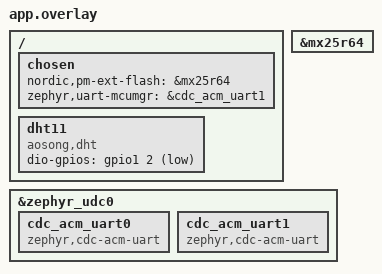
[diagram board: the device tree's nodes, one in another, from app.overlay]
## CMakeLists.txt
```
#
# Copyright (c) 2020 Nordic Semiconductor ASA
#
# SPDX-License-Identifier: LicenseRef-Nordic-5-Clause
#
cmake_minimum_required(VERSION 3.20.0)

find_package(Zephyr REQUIRED HINTS $ENV{ZEPHYR_BASE})
project(chat)

# NORDIC SDK APP START
target_sources(app PRIVATE
	src/main.c
	src/model_handler.c
	src/flash_storage.c)
target_include_directories(app PRIVATE include)
# NORDIC SDK APP END
```

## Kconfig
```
mainmenu "Mesh Node Application"

source "Kconfig.zephyr"

config APP_ENABLE_DFU
    bool "Enable DFU (MCUmgr + External Flash)"
    default y
    help
      Enables MCUmgr, and memory layout for DFU. Disable this for faster dev builds.
      NOTE: You must also enable/disable SB_CONFIG_BOOTLOADER_MCUBOOT in sysbuild.conf!

    # MCUmgr
    select MCUMGR
    select MCUMGR_GRP_OS
    select MCUMGR_GRP_IMG
    select MCUMGR_TRANSPORT_UART
    select IMG_MANAGER
    
    # Memory Layout (External Flash)
    # This tells the partition manager to use the external flash for the secondary slot
    select PM_EXTERNAL_FLASH_MCUBOOT_SECONDARY

    # USB stack - an extra USB CDC Port has to be exposed to the host
    select USB_COMPOSITE_DEVICE
```

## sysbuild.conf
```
# MCUboot
# SB_CONFIG_BOOTLOADER_MCUBOOT=y
# MCUboot should use external flash
# SB_CONFIG_PM_EXTERNAL_FLASH_MCUBOOT_SECONDARY=y

# Config for signing with custom private key
# SB_CONFIG_BOOT_SIGNATURE_KEY_FILE="\${APP_DIR}/private_key.pem"
# SB_CONFIG_BOOT_SIGNATURE_TYPE_ECDSA_P256=y
```

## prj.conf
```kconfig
#
# Copyright (c) 2020 Nordic Semiconductor ASA
#
# SPDX-License-Identifier: LicenseRef-Nordic-5-Clause
#
CONFIG_NCS_SAMPLES_DEFAULTS=y
CONFIG_LOG_MODE_DEFERRED=y

# Config DFU
CONFIG_APP_ENABLE_DFU=n

CONFIG_SENSOR=y
CONFIG_DHT=y

# Dependencies
# Configure dependencies for CONFIG_MCUMGR  
CONFIG_NET_BUF=y
CONFIG_ZCBOR=y
CONFIG_CRC=y

# Flash configs
CONFIG_PARTITION_MANAGER_ENABLED=y
CONFIG_FLASH=y
CONFIG_STREAM_FLASH=y
CONFIG_FLASH_MAP=y
CONFIG_NORDIC_QSPI_NOR_FLASH_LAYOUT_PAGE_SIZE=4096

# Configure dependencies for CONFIG_MCUMGR_TRANSPORT_UART 
CONFIG_BASE64=y

# Enable QSPI driver for Application
CONFIG_NORDIC_QSPI_NOR=y

# Enable USB subsystem
CONFIG_USB_DEVICE_STACK=y
CONFIG_UART_LINE_CTRL=y
CONFIG_USB_CDC_ACM_RINGBUF_SIZE=1024
CONFIG_USB_DEVICE_INITIALIZE_AT_BOOT=n
CONFIG_USB_DEVICE_PID=0x5301
CONFIG_USB_DEVICE_VID=0x1915
CONFIG_USB_DEVICE_PRODUCT="Sensor Node Gateway"

# General configuration
CONFIG_NCS_APPLICATION_BOOT_BANNER_STRING="Sensor Base"
CONFIG_SYSTEM_WORKQUEUE_STACK_SIZE=2048
# Flash shell module uses 8k of RAM for testing buffers, disable to save RAM
CONFIG_FLASH_SHELL=n
CONFIG_NVS=y
CONFIG_NVS_LOOKUP_CACHE=y
CONFIG_SETTINGS=y
CONFIG_SETTINGS_NVS_NAME_CACHE=y
CONFIG_HWINFO=y
CONFIG_DK_LIBRARY=y
CONFIG_PM_PARTITION_SIZE_SETTINGS_STORAGE=0x8000
CONFIG_SOC_FLASH_NRF_PARTIAL_ERASE=y

# Bluetooth configuration
CONFIG_BT=y
CONFIG_BT_DEVICE_NAME="Sensor Base"
CONFIG_BT_L2CAP_TX_BUF_COUNT=8
CONFIG_BT_OBSERVER=y
CONFIG_BT_PERIPHERAL=y
CONFIG_BT_SETTINGS=y

# Disable unused Bluetooth features
CONFIG_BT_CTLR_LE_ENC=n
CONFIG_BT_PHY_UPDATE=n
CONFIG_BT_CTLR_CHAN_SEL_2=n
CONFIG_BT_CTLR_MIN_USED_CHAN=n
CONFIG_BT_CTLR_PRIVACY=n

# Bluetooth Mesh configuration
CONFIG_BT_MESH=y
CONFIG_BT_MESH_RELAY=y
CONFIG_BT_MESH_FRIEND=y
CONFIG_BT_MESH_RX_SEG_MAX=10
CONFIG_BT_MESH_TX_SEG_MAX=10
CONFIG_BT_MESH_PB_GATT=y
CONFIG_BT_MESH_GATT_PROXY=y
CONFIG_BT_MESH_PROXY_USE_DEVICE_NAME=y
CONFIG_BT_MESH_SUBNET_COUNT=2
CONFIG_BT_MESH_APP_KEY_COUNT=3
CONFIG_BT_MESH_MODEL_KEY_COUNT=3
CONFIG_BT_MESH_CRPL=32
CONFIG_BT_MESH_MSG_CACHE_SIZE=64
CONFIG_BT_MESH_DK_PROV=n

# Enable Bluetooth Mesh models debug logs
CONFIG_BT_MESH_LOG_LEVEL_DBG=y

CONFIG_LOG_BACKEND_RTT=n
```

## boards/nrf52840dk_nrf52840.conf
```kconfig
#
# Copyright (c) 2024 Nordic Semiconductor ASA
#
# SPDX-License-Identifier: LicenseRef-Nordic-5-Clause
#
################################################################################
# Application overlay - nrf52dk_nrf52840

CONFIG_SOC_FLASH_NRF_PARTIAL_ERASE=n
CONFIG_SENSOR=y
CONFIG_DHT=y
```

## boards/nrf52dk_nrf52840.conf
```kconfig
#
# Copyright (c) 2024 Nordic Semiconductor ASA
#
# SPDX-License-Identifier: LicenseRef-Nordic-5-Clause
#
################################################################################
# Application overlay - nrf52dk_nrf52840

CONFIG_SOC_FLASH_NRF_PARTIAL_ERASE=n
```

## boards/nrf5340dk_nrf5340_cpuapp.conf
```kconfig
CONFIG_SYSTEM_WORKQUEUE_STACK_SIZE=4096
# Use deferred logging
CONFIG_NCS_SAMPLES_DEFAULTS=n
CONFIG_LOG=y
CONFIG_ASSERT=y
CONFIG_ASSERT_NO_COND_INFO=y
CONFIG_ASSERT_NO_MSG_INFO=y
CONFIG_HW_STACK_PROTECTION=y
```

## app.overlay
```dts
&mx25r64 {
	status = "okay";
};

&zephyr_udc0 {
	cdc_acm_uart0: cdc_acm_uart0 {
		compatible = "zephyr,cdc-acm-uart";
	};

	cdc_acm_uart1: cdc_acm_uart1 {
        compatible = "zephyr,cdc-acm-uart";
    };
};

/ {
	chosen {
		nordic,pm-ext-flash = &mx25r64;
		zephyr,uart-mcumgr = &cdc_acm_uart1;
	};

	dht11: dht11 {
		compatible = "aosong,dht";
		status = "okay";
		dio-gpios = <&gpio1 2 (GPIO_PULL_UP | GPIO_ACTIVE_LOW)>;
	};
};
```

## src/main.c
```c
/*
 * Copyright (c) 2024 Nordic Semiconductor ASA
 *
 * SPDX-License-Identifier: LicenseRef-Nordic-5-Clause
 */

#include <zephyr/kernel.h>
#include <zephyr/bluetooth/bluetooth.h>
#include <zephyr/bluetooth/mesh.h>
#include <zephyr/logging/log.h>
#include <zephyr/settings/settings.h>
#include <dk_buttons_and_leds.h>
#include <zephyr/drivers/hwinfo.h>
#include <zephyr/sys/reboot.h>
#include <zephyr/drivers/uart.h>
#include <zephyr/usb/usb_device.h>
#include <zephyr/drivers/gpio.h>
#include <zephyr/devicetree.h>
#include <pm_config.h>
#include <zephyr/drivers/flash.h>
#include <zephyr/storage/flash_map.h>
#include <zephyr/sys/byteorder.h>
#include "model_handler.h"
#include "flash_storage.h"

#if defined(CONFIG_SOC_SERIES_NRF52X)
#include <zephyr/drivers/sensor.h>
#endif

LOG_MODULE_REGISTER(main, LOG_LEVEL_INF);

// TODO: Remove this counter once data is available from sensors
static uint32_t app_counter = 0;
static struct gpio_callback btn_cb;
static enum usb_dc_status_code current_usb_status = USB_DC_DISCONNECTED;
static bool is_central = false;

#if defined(CONFIG_SOC_SERIES_NRF52X)
const struct device *dht11 = DEVICE_DT_GET(DT_NODELABEL(dht11));
#endif

#define SNS_READ_INTERVAL_MS 60000
#define SNS_THREAD_STACK_SIZE 1024
#define SNS_THREAD_PRIORITY 7
#define SENDER_THREAD_STACK_SIZE 2048
#define SENDER_THREAD_PRIORITY 7
#define ERASE_FLASH_THREAD_STACK_SIZE 1024
#define ERASE_FLASH_THREAD_PRIORITY 7
#define SNS_Q_SIZE MAX_BATCH_SIZE
K_MSGQ_DEFINE(sns_msg_q, sizeof(struct sensor_message), SNS_Q_SIZE, 4);

// Semaphore for the thread reading the sensors
K_SEM_DEFINE(sample_sem, 0, 1);
// Semaphore for the thread that handles the queued readings
K_SEM_DEFINE(send_samples_sem, 0, 1);
// Semaphore for the thread that calls the erase flash function
K_SEM_DEFINE(erase_flash_sem, 0, 1);

// Get devicetree node identifiers for LEDs and buttons
#define LED0_NODE DT_ALIAS(led0)
#define LED1_NODE DT_ALIAS(led1)
#define LED2_NODE DT_ALIAS(led2)
#define LED3_NODE DT_ALIAS(led3)

#define BTN0_NODE DT_ALIAS(sw0)
#define BTN1_NODE DT_ALIAS(sw1)
#define BTN2_NODE DT_ALIAS(sw2)
#define BTN3_NODE DT_ALIAS(sw3)

static const struct gpio_dt_spec leds[] = {
    GPIO_DT_SPEC_GET(LED0_NODE, gpios),
    GPIO_DT_SPEC_GET(LED1_NODE, gpios),
    GPIO_DT_SPEC_GET(LED2_NODE, gpios),
    GPIO_DT_SPEC_GET(LED3_NODE, gpios)
};

#define USB_CONN_LED (leds[0])
#define CENTRAL_LED  (leds[1])
#define LED_ON       1
#define LED_OFF      0


// Function that will be passed as cb to model_handler
static void led_control(uint32_t led_mask) {
    for (uint8_t i = 0; i < ARRAY_SIZE(leds); i++) {
        if (led_mask & BIT(i))
            gpio_pin_set_dt(&(leds[i]), LED_ON);
        else
            gpio_pin_set_dt(&(leds[i]), LED_OFF);
    }
}

static const struct gpio_dt_spec btns[] = {
    GPIO_DT_SPEC_GET(BTN0_NODE, gpios),
    GPIO_DT_SPEC_GET(BTN1_NODE, gpios),
    GPIO_DT_SPEC_GET(BTN2_NODE, gpios),
    GPIO_DT_SPEC_GET(BTN3_NODE, gpios)
};

static void button_handler(const struct device *dev, struct gpio_callback *cb, uint32_t pins) {
    // Check if any of the buttons has triggered this interrupt
    // All buttons are on GPIO Port 0, so it's safe to check *dev against a single button
    if (dev == btns[0].port) {
        if (pins & BIT(btns[0].pin)) {
            // Pressing btn0 (Button 1 on the board) generates a new sample
            k_sem_give(&sample_sem);
        }

        if (pins & BIT(btns[1].pin)) {
            // Pressing btn1 (Button 2 on the board) handles existing readings stored in queue
            k_sem_give(&send_samples_sem);
        }

        if (pins & BIT(btns[2].pin)) {
            // Pressing btn2 (Button 3 on the board) clears the external flash
            k_sem_give(&erase_flash_sem);
        }
    }
}

// UUID so device is recognised, value will be the same correspond as the MCU HW UUID
static uint8_t dev_uuid[16];

// Boolean for available USB connection status - true if board is connected to a host via the MCU USB header
static volatile bool is_usb_conn = false;

// Get the CDC ACM UART device from the Overlay
const struct device *usb_uart_dev = DEVICE_DT_GET(DT_NODELABEL(cdc_acm_uart0));

static void uart_rx_cb(const struct device *dev, void *user_data) {
    if (!uart_irq_update(dev)) {
        return;
    }

    if (uart_irq_rx_ready(dev)) {
        uint8_t c;
        while (uart_fifo_read(dev, &c, 1) == 1) {
            // Simple command parse - receiving 'C' lets the node know it's now the central
            if (c == 'C') {
                LOG_INF("Received 'Set Central'");
                model_handler_est_central();
                gpio_pin_set_dt(&CENTRAL_LED, LED_ON);
                is_central = true;
            } else if (c == 'D') {
                LOG_INF("Received 'Cancel Central'");
                model_handler_cancel_central();
                gpio_pin_set_dt(&CENTRAL_LED, LED_OFF);
            }
        }
    }
}

static void gateway_data_handler(const uint8_t *data, const uint8_t len, const uint16_t addr) {
    if (!is_central || !device_is_ready(usb_uart_dev)) {
        return;
    }

    uint8_t usb_buf[MAX_SNS_MSG_LEN + 10]; // Buffer for central, should be large enough to fit incoming message + serial protocol overhead
    
    // Copy the data into local buffer
    // The 4 byte offset is to leave space for the protocol header 
    memcpy(usb_buf+4, data, len);
    
    // Add sync bytes
    usb_buf[0] = 'R';
    usb_buf[1] = 'X';
    
    // Add sender address
    usb_buf[2] = (uint8_t)(addr & 0xFF); // Extract low byte
    usb_buf[3] = (uint8_t)(addr >> 8); // Extract high byte
    
    // Add end byte
    usb_buf[4+len] = '\0';

    // Send data over USB
    for (uint8_t i = 0; i < 4+len+1; i++) {
        uart_poll_out(usb_uart_dev, usb_buf[i]);
    }
}

static void provisioning_complete(uint16_t net_idx, uint16_t addr) {
    LOG_INF("Provisioning complete! NetIdx: 0x%04x, Address: 0x%04x", net_idx, addr);
    configure_model();
}

static void provisioning_reset(void) {
    // Connection settings should be wiped by the stack when a node is reset by the provisioner
    // Rebooting should ensure that advertising starts from a clean state
    // TODO: Add network core force off before reboot if there are issues with peripherals after a restart.
    LOG_WRN("Node reset. Rebooting.");
    sys_reboot(SYS_REBOOT_WARM);
}

static const struct bt_mesh_prov prov = {
    .uuid = dev_uuid,
    .complete = provisioning_complete,
    .reset = provisioning_reset,
};

static void usb_status_cb(enum usb_dc_status_code cb_status, const uint8_t *param) {
    current_usb_status = cb_status;
    switch (cb_status) {
        case USB_DC_CONNECTED: 
            LOG_INF("USB Power");
            break;
        case USB_DC_CONFIGURED:
            LOG_INF("USB Configured");
            is_usb_conn = true;
            gpio_pin_set_dt(&USB_CONN_LED, LED_ON);
            
            // Start listening for 'Set Central' command
            uart_irq_rx_enable(usb_uart_dev);
            break;
        case USB_DC_RESUME:
            LOG_INF("USB Resumed");
            is_usb_conn = true;
            gpio_pin_set_dt(&USB_CONN_LED, LED_ON);
            uart_irq_rx_enable(usb_uart_dev);
            break;
        case USB_DC_DISCONNECTED:
        case USB_DC_SUSPEND:
            LOG_INF("USB Disconnected");
            is_usb_conn = false;
            gpio_pin_set_dt(&USB_CONN_LED, LED_OFF);
            gpio_pin_set_dt(&CENTRAL_LED, LED_OFF);

            // Stop listening to USB port
            uart_irq_rx_disable(usb_uart_dev);
            // Let the other devices know this node is no longer a central
            if (is_central) {
                gpio_pin_set_dt(&CENTRAL_LED, LED_OFF);
                is_central = false;
                model_handler_cancel_central();
            }
            break;
        default:
            ;
            break;
    }
}

static void enq_reading(struct k_msgq *q, const struct sensor_message *sm) {
    // TODO: Revisit and evaluate if 20ms of wait time is an acceptable value 
    int err = k_msgq_put(q, sm, K_MSEC(20));
    if (err == -ENOMSG || err == -EAGAIN) {
        // Queue is probably full. Remove an element and try again
        struct sensor_message temp;
        k_msgq_get(q, &temp, K_MSEC(50));
        if (k_msgq_put(q, sm, K_MSEC(200))) {
            LOG_WRN("Unable to add reading to queue");
        }
        else {
            LOG_DBG("Queue full, overwrote old sample");
        }
    } else {
        LOG_DBG("Sample enqueued. Count: %u", k_msgq_num_used_get(q));
    }
}

// Function that reads sensors (simulated for now) and adds received values to a queue of readings
static void gen_samples_and_enq(void) {
    static struct sensor_message msg;

    app_counter++;
    msg.timestamp = k_uptime_get_32();

#if defined(CONFIG_SOC_SERIES_NRF52X)
    int err = sensor_sample_fetch(dht11);
    if (err) {
        LOG_ERR("Failed to get sample from DHT11 (err %d)", err);
        return;
    }

    struct sensor_value temp;
    struct sensor_value humid;

    err = sensor_channel_get(dht11, SENSOR_CHAN_AMBIENT_TEMP, &temp);
    if (!err) {
        LOG_WRN("GOT TEMP: %d.%d", temp.val1, temp.val2/10000);
        msg.type = SENSOR_TYPE_TEMP_C;
        msg.value = temp.val1*100 + temp.val2/10000;
        enq_reading(&sns_msg_q, &msg);

        err = sensor_channel_get(dht11, SENSOR_CHAN_HUMIDITY, &humid);
        if (err) {
            LOG_ERR("Failed to read humidity from DHT11 (err %d)", err);
        } else {
            LOG_WRN("GOT HUMID: %d.%d", humid.val1, humid.val2/10000);
            msg.type = SENSOR_TYPE_HUMID_PC;
            msg.value = humid.val1*100 + humid.val2/10000;
            enq_reading(&sns_msg_q, &msg);
        }
    } else {
        LOG_ERR("Failed to read temperature from DHT11 (err %d)", err);
    }
#elif defined(CONFIG_SOC_SERIES_NRF53X)
    // Generate a counter reading
    msg.type = SENSOR_TYPE_COUNTER;
    msg.value = app_counter;
    // Try to queue message
    enq_reading(&sns_msg_q, &msg);

    // Generate a temperature or humidity reading
    if (app_counter % 2) {
        msg.type = SENSOR_TYPE_TEMP_C;
        msg.value = 2450 + (app_counter % 50); // For some variation in the values
        if (app_counter % 8) {
            msg.value = -msg.value;
        }
    } else {
        msg.type = SENSOR_TYPE_HUMID_PC;
        msg.value = 50 + (10 - (app_counter % 21));
    }
    enq_reading(&sns_msg_q, &msg);
#endif
    // If the queue is almost full, try to empty it
    if (k_msgq_num_free_get(&sns_msg_q) < 2) {
        k_sem_give(&send_samples_sem);
    }
}

// Thread that reads sensors periodically
static void sns_thread_f(void *p1, void *p2, void *p3) {
    int ret = 0;
    while (1) {
        ret = k_sem_take(&sample_sem, K_MSEC(SNS_READ_INTERVAL_MS));
        LOG_INF("Generating samples");
        gen_samples_and_enq();
    }
}

K_THREAD_DEFINE(sns_thread, SNS_THREAD_STACK_SIZE, sns_thread_f, 
                NULL, NULL, NULL, SNS_THREAD_PRIORITY, 0, 0);

// Thread to offload sending from the button interrupt handler
static void sender_thread_f(void *p1, void *p2, void *p3) {
    int ret = 0, err = 0;
    struct sensor_message batch[MAX_BATCH_SIZE];
    uint8_t buf[MAX_SNS_MSG_LEN];
    
    while (1) {
        ret = k_sem_take(&send_samples_sem, K_FOREVER);

        if (ret) {
            LOG_ERR("Failed to take send_sample_sem");
            continue;
        }

        // Peek to check if there is data to process
        while (k_msgq_num_used_get(&sns_msg_q) > 0) { 
            uint8_t count = 0;
    
            // Prepare Batch
            while (count < MAX_BATCH_SIZE && k_msgq_get(&sns_msg_q, &batch[count], K_MSEC(10)) == 0) {
                count++;
            }
    
            if (count) {
                if (is_central) {
                    // If the node is the central, send data over USB directly
                    // Also announce that node is central in case any other nodes joined the network
                    // and are unaware
                    model_handler_est_central();
                    memset(buf, 0, sizeof(buf));
                    buf[0] = count;
                    int offset = 1;

                    // Serialize the batch
                    for (int i = 0; i < count; i++) {
                        buf[offset++] = batch[i].type;

                        sys_put_le32(batch[i].timestamp, &buf[offset]);
                        offset += sizeof(batch[i].timestamp);

                        sys_put_le32(batch[i].value, &buf[offset]);
                        offset += sizeof(batch[i].value);
                    }

                    gateway_data_handler(buf, offset, get_central_address());
                } else if (central_exists()) {
                    // try to send data to central
                    err = model_handler_send(batch, count);
                    
                    if (err == -EBUSY) {
                        LOG_WRN("Mesh stack busy (err %d), reattempting transmission shortly", err);

                        k_msleep(1000);
                        err = model_handler_send(batch, count);
                        if (err) {
                            LOG_ERR("Retransmission failed (err %d). Storing data in flash", err);

                            for (int i = 0; i < count; i++) {
                                flash_storage_write(&batch[i]);
                            }
                        }
                    }
                } else {
                    // Node isn't connected to USB and no central is available, store readings in flash
                    LOG_INF("No connection available (USB or Mesh), storing data in flash");
                    for (int i = 0; i < count; i++) {
                        flash_storage_write(&batch[i]);
                    }
                }
            }
        }
    }
}

K_THREAD_DEFINE(sender_thread, SENDER_THREAD_STACK_SIZE, sender_thread_f, 
                NULL, NULL, NULL, SENDER_THREAD_PRIORITY, 0, 0);

static void erase_flash_thread_f(void *p1, void *p2, void *p3) {
    int err = 0;
    while (1) {
        k_sem_take(&erase_flash_sem, K_FOREVER);
        LOG_INF("Erasing flash");
        err = flash_storage_clear();
        if (err) {
            LOG_ERR("Flash erase failed (err %d)", err);
        }
    }
}

K_THREAD_DEFINE(erase_flash_thread, ERASE_FLASH_THREAD_STACK_SIZE, erase_flash_thread_f, 
                NULL, NULL, NULL, ERASE_FLASH_THREAD_PRIORITY, 0, 0);

int main(void)
{
    int err;

    LOG_INF("Initializing Bare-Bones BLE Mesh Vendor Sample");

    // Check if LED and Buttons port is ready - they are all on port 0
    if (!device_is_ready(leds[0].port)) {
        LOG_ERR("LEDs and Buttons GPIO port is not ready");
        return 0;
    }

    // Configure LED pins
    for (uint8_t i = 0; i < ARRAY_SIZE(leds); i++) {
        err = gpio_pin_configure_dt(&(leds[i]), GPIO_OUTPUT_ACTIVE);
        if (err) {
            LOG_ERR("LEDs configuration failed (err %d)", err);
            return err;
        }
    }

    // Configure Button pins
    for (uint8_t i = 0; i < ARRAY_SIZE(btns); i++) {
        err = gpio_pin_configure_dt(&(btns[i]), GPIO_INPUT);
        if (err) {
            LOG_ERR("Buttons configuration failed (err %d)", err);
            return err;
        }
    }

    // Configure Button interrupts
    for (uint8_t i = 0; i < ARRAY_SIZE(btns); i++) {
        err = gpio_pin_interrupt_configure_dt(&(btns[i]), GPIO_INT_EDGE_TO_ACTIVE);
        if (err) {
            LOG_ERR("Button interrupts config failed (err %d)", err);
            return err;
        }
    } 

    // Configure Button interrupt callback
    // Create mask that includes all buttons
    uint32_t btn_mask = 0;
    for (uint8_t i = 0; i < ARRAY_SIZE(btns); i++) {
        btn_mask |= BIT(btns[i].pin);
    }
    // Init cb structure
    gpio_init_callback(&btn_cb, button_handler, btn_mask);
    // Add cb to buttons
    for (uint8_t i = 0; i < ARRAY_SIZE(btns); i++) {
        err = gpio_add_callback(btns[i].port, &btn_cb);
		if (err) {
			LOG_ERR("Cannot add callback (err %d)", err);
			return err;
		}
    }

    err = flash_storage_init();
    if (err) {
        LOG_ERR("Flash Storage Init Failed (%d)", err);
    }

    err = model_handler_init((struct model_cbs) {.gw_cb = gateway_data_handler, .led_cb = led_control});
    if (err) {
        LOG_ERR("Model handler init failed (err %d)", err);
        return err;
    }

#if defined(CONFIG_SOC_SERIES_NRF52X)
    if (!dht11) {
        LOG_ERR("DHT sensor not found");
    } else if (!device_is_ready(dht11)) {
        LOG_ERR("DHT sensor not ready");
    } else {
        LOG_INF("DHT sensor found and ready");
    }
#endif

    if (!device_is_ready(usb_uart_dev)) {
        LOG_ERR("CDC ACM device not ready");
        return -ENODEV;
    }

    // Configure UART Interrupt Callback
    uart_irq_callback_user_data_set(usb_uart_dev, uart_rx_cb, NULL);

    // Enable USB stack for DFU and recovery
    if (IS_ENABLED(CONFIG_USB_DEVICE_STACK)) {
		int err = usb_enable(usb_status_cb);
		if (err) {
            LOG_ERR("USB stack init failed (err %d)", err);
			return 0;
		}
	}

    err = bt_enable(NULL);
    if (err) {
        LOG_ERR("Bluetooth init failed (err %d)", err);
        return err;
    }
    LOG_INF("Bluetooth initialized");

    err = hwinfo_get_device_id(dev_uuid, sizeof(dev_uuid));
    if (err < 0) {
        LOG_WRN("Failed to get device ID (err %d), using random UUID", err);
        bt_rand(dev_uuid, sizeof(dev_uuid));
    }

    // Provisioning data is populated above
    // Composition data is populated in model_handler.c
    err = bt_mesh_init(&prov, &comp);
    if (err) {
        LOG_ERR("Mesh init failed (err %d)", err);
        return err;
    }

    // Reload connection data if persistent storage is configured
	if (IS_ENABLED(CONFIG_SETTINGS)) {
		settings_load();
	}

    // Start advertising
	// This will be a no-op if settings_load() loaded provisioning info
	bt_mesh_prov_enable(BT_MESH_PROV_ADV | BT_MESH_PROV_GATT);

    LOG_INF("Mesh initialized. Waiting for provisioning...");
    LOG_INF("Once provisioned, press button 1 to generate data");

    // Enable all LEDs as a sign that the app has started. This can be useful after a DFU, as 
    // the bootloader may take a while to copy the new image and launch it
    for (uint8_t i = 0; i < ARRAY_SIZE(leds); i++) {
        gpio_pin_set_dt(&(leds[i]), LED_ON);
    }
    // The LEDs can be turned off after 700ms. Blocking delay is ok atm since main isn't doing anything else after this point.
    k_msleep(700);
    for (uint8_t i = 0; i < ARRAY_SIZE(leds); i++) {
        gpio_pin_set_dt(&(leds[i]), LED_OFF);
    }
    // Turn the USB Conn LED back on if the board is connected to a host
    if (is_usb_conn)
        gpio_pin_set_dt(&USB_CONN_LED, LED_ON);
    if (is_central)
        gpio_pin_set_dt(&CENTRAL_LED, LED_ON);
        
    return 0;
}
```

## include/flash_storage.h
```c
/*
 * flash_storage.h
 *
 * Slot-Based Circular Buffer on Raw Flash.
 */

#ifndef FLASH_STORAGE_H__
#define FLASH_STORAGE_H__

#include <zephyr/kernel.h>
#include <zephyr/drivers/flash.h>
#include "model_handler.h" 

// Maximum entries to buffer in RAM for batch operations
#define FLASH_BATCH_SIZE 10

/**
 * @brief Initialize the flash storage system.
 * Scans metadata to restore the write cursor.
 * @return 0 on success, negative errno on failure.
 */
int flash_storage_init(void);

/**
 * @brief Store a single reading.
 * Writes to the current sector. If full, moves to next sector and erases it.
 * @param msg The sensor reading to store.
 */
void flash_storage_write(const struct sensor_message *msg);

/**
 * @brief Read readings from storage.
 * Reads 'count' items from the ACTIVE slot (newest data).
 * @param msgs Output buffer.
 * @param count Max number to read.
 * @return Number of items read.
 */
int flash_storage_read(struct sensor_message *msgs, int count);

/**
 * @brief Get total number of stored records across all slots.
 */
uint32_t flash_storage_get_count(void);

/**
 * @brief Wipe the entire storage partition.
 */
int flash_storage_clear(void);

#endif /* FLASH_STORAGE_H__ */
```

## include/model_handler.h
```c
#ifndef MODEL_HANDLER_H__
#define MODEL_HANDLER_H__

#include <zephyr/bluetooth/mesh.h>

// Test company and vendor ID
#define TEST_VND_COMPANY_ID 0xFFFF
#define TEST_VND_MODEL_ID   0x0001

// Custom OpCode: 3-byte header for Vendor Models (C0 | ID) + Company ID
#define BT_MESH_MODEL_OP_MESSAGE BT_MESH_MODEL_OP_3(0x01, TEST_VND_COMPANY_ID)
#define BT_MESH_MODEL_OP_EST_CENTRAL BT_MESH_MODEL_OP_3(0x02, TEST_VND_COMPANY_ID)
#define BT_MESH_MODEL_OP_CANCEL_CENTRAL BT_MESH_MODEL_OP_3(0x03, TEST_VND_COMPANY_ID)

// Maximum amount of readings in a single transmission
#define MAX_BATCH_SIZE 10

// Callback type for sending data to the Gateway
typedef void (*gateway_data_cb_t)(const uint8_t *data_buf, const uint8_t len, const uint16_t addr);

// Callback for LED control
typedef void (*led_control_cb_t)(uint32_t led_mask);

// Structure to hold and pass the callbacks
struct model_cbs {
    /**
     * This callback is used by all nodes whenever a packet is received, but it only has an effect
     * if the node also acts as a gateway (is connected to a host via USB).
     */
    gateway_data_cb_t gw_cb;

    /**
     * Callback used by the health server to blink the LEDs during provisioning.
     */
    led_control_cb_t led_cb;
};

// Sensor types that the node can read and send data for
enum sensor_type {
    SENSOR_TYPE_COUNTER = 0,
    SENSOR_TYPE_TEMP_C,
    SENSOR_TYPE_HUMID_PC,
    SENSOR_TYPE_BATT_MV,
};

// Payload structure - limited to 9 bytes for now so it can use unfragmented transmission
struct sensor_message {
    uint8_t type; // Using enum sensor_type would make this field 4 bits, as it would be considered an int
    uint32_t timestamp;
    int32_t value;
};
#define SENSOR_PAYLOAD_LEN (sizeof(uint8_t) + sizeof(uint32_t) + sizeof(int32_t))
// Minimum length of over the air message - 1 byte for count + 1 sensor reading
#define MIN_SNS_MSG_LEN (1 + SENSOR_PAYLOAD_LEN)
#define MAX_SNS_MSG_LEN (1 + (MAX_BATCH_SIZE * SENSOR_PAYLOAD_LEN))

// Mesh model composition
extern const struct bt_mesh_comp comp;

/**
 * @brief Set default publication and subscription parameters (group address, TTL and retransmission policy)
 */
void configure_model(void);

/**
 * @brief Initialize the mesh model subsystem
 * @param _mdl_cbs Struct containing function pointers to the callback implementations
 * @return 0 on success, negative error code otherwise
 */
int model_handler_init(const struct model_cbs _mdl_cbs);

/**
 * @brief Send a structured sensor message
 * @param msgs Array of sensor messages
 * @param count Number of messages in the array
 * @return 0 on success, or negative error code
 */
int model_handler_send(struct sensor_message *msgs, uint8_t count);

/**
 * @brief Establish if a node becomes a central when it's connected to a USB port
 * @return 0 on success or negative error code
 */
int model_handler_est_central(void);

/**
 * @brief Called when a node is disconnected from its USB host to cancel its status as a central;
 * @return on success or negative error code
 */
int model_handler_cancel_central(void);

/**
 * @brief Get the mesh address of the node
 * @return mesh address
 */
uint16_t get_central_address();

/**
 * @brief Check if a central node is known
 * @return 1 if there is a central node, 0 otherwise
 */
bool central_exists();

#endif /* MODEL_HANDLER_H__ */
```

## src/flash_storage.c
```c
/*
 * flash_storage.c
 */

#include <zephyr/kernel.h>
#include <zephyr/logging/log.h>
#include <zephyr/devicetree.h>
#include <zephyr/drivers/flash.h>
#include <zephyr/sys/byteorder.h>
#include <zephyr/sys/util.h>
#include "flash_storage.h"
#include <pm_config.h> 

LOG_MODULE_REGISTER(flash_storage, LOG_LEVEL_INF);

// Flash layout configs
#define SECTOR_SIZE             CONFIG_NORDIC_QSPI_NOR_FLASH_LAYOUT_PAGE_SIZE
#define STORAGE_PARTITION_ID    PM_DATA_STORAGE_ID
#define STORAGE_START_OFFSET    PM_DATA_STORAGE_OFFSET
#define STORAGE_TOTAL_SIZE      PM_DATA_STORAGE_SIZE
const struct device *flash_dev = DEVICE_DT_GET(DT_CHOSEN(nordic_pm_ext_flash));

/** 
 * Layout:
 * Slots 0..N-1: Data
 * Slot N: Metadata
 */
#define META_SECTOR_SIZE        SECTOR_SIZE
#define MAX_SLOTS               ((STORAGE_TOTAL_SIZE / SECTOR_SIZE) - 1)
#define USED_SLOTS              2
#define META_REGION_ADDR        (STORAGE_START_OFFSET + (USED_SLOTS * SECTOR_SIZE))

// Align entry to 4 bytes
#define ENTRY_SIZE              ROUND_UP(sizeof(struct sensor_message), 4)
#define ENTRIES_PER_SECTOR      (SECTOR_SIZE / ENTRY_SIZE)

// Persistent Context
#define CTX_MAGIC               0xDEADBEEF

struct flash_ctx {
    uint32_t magic;
    uint32_t current_slot;           // Index 0 to USED_SLOTS-1
    uint32_t write_offset;           // Byte offset within the current slot
    uint32_t total_count;            // Total records stored (approx)
    uint8_t  slot_valid[USED_SLOTS]; // 1 if slot is full
};

// In-Memory State
static struct flash_ctx ctx;
static uint32_t meta_write_offset = 0;

static bool is_blank(const uint8_t *buf, size_t len)
{
    for (size_t i = 0; i < len; i++) {
        if (buf[i] != 0xFF) return false;
    }
    return true;
}

static int save_context(void)
{
    ctx.magic = CTX_MAGIC;

    // Check if meta sector is full
    if (meta_write_offset + sizeof(struct flash_ctx) > META_SECTOR_SIZE) {
        LOG_INF("Meta sector full, erasing");
        int err = flash_erase(flash_dev, META_REGION_ADDR, META_SECTOR_SIZE);
        if (err != 0) return err;
        meta_write_offset = 0;
    }

    int err = flash_write(flash_dev, META_REGION_ADDR + meta_write_offset, &ctx, sizeof(struct flash_ctx));
    if (err == 0) {
        meta_write_offset += sizeof(struct flash_ctx);
    }
    return err;
}

int flash_storage_init(void)
{
    if (!device_is_ready(flash_dev)) {
        LOG_ERR("Flash device not ready");
        return -ENODEV;
    }

    // Restore Context
    struct flash_ctx temp;
    uint32_t off = 0;
    bool found = false;

    while (off + sizeof(struct flash_ctx) <= META_SECTOR_SIZE) {
        int err = flash_read(flash_dev, META_REGION_ADDR + off, &temp, sizeof(temp));
        if (err != 0) return err;

        if (temp.magic == CTX_MAGIC) {
            ctx = temp;
            found = true;
        } else if (is_blank((uint8_t *)&temp, sizeof(temp))) {
            meta_write_offset = off;
            break;
        }
        off += sizeof(struct flash_ctx);
    }

    if (!found) {
        LOG_INF("No context found. Formatting");
        ctx.magic = CTX_MAGIC;
        ctx.current_slot = 0;
        ctx.write_offset = 0;
        ctx.total_count = 0;
        memset(ctx.slot_valid, 0, sizeof(ctx.slot_valid));
        meta_write_offset = 0;
        
        // Erase first data slot to be ready
        flash_erase(flash_dev, STORAGE_START_OFFSET, SECTOR_SIZE);
        save_context();
    } else {
        if (off >= META_SECTOR_SIZE) meta_write_offset = META_SECTOR_SIZE;
    }

    LOG_INF("Storage Ready: Slot %d, Offset %d, Count %d", 
            ctx.current_slot, ctx.write_offset, ctx.total_count);
    return 0;
}

void flash_storage_write(const struct sensor_message *msg)
{
    // Check if current slot is full
    if (ctx.write_offset + ENTRY_SIZE > SECTOR_SIZE) {
        // Move to next slot
        ctx.slot_valid[ctx.current_slot] = 1; // Mark old slot as full/valid
        
        ctx.current_slot = (ctx.current_slot + 1) % USED_SLOTS;
        LOG_INF("Switching to slot %d", ctx.current_slot);
        ctx.write_offset = 0;
        
        
        // Check if the new target slot already has data (Wrapping around)
        if (ctx.slot_valid[ctx.current_slot]) {
            // A full sector of old data is getting erased
            if (ctx.total_count >= ENTRIES_PER_SECTOR) {
                ctx.total_count -= ENTRIES_PER_SECTOR;
            } else {
                ctx.total_count = 0; // Should not happen if logic is correct
            }
        }
        
        // Erase the new target slot
        uint32_t sector_addr = STORAGE_START_OFFSET + (ctx.current_slot * SECTOR_SIZE);
        flash_erase(flash_dev, sector_addr, SECTOR_SIZE);

        // Mark new slot as technically valid (in use)
        ctx.slot_valid[ctx.current_slot] = 1; 
    }

    // Write to Flash
    uint32_t addr = STORAGE_START_OFFSET + (ctx.current_slot * SECTOR_SIZE) + ctx.write_offset;
    int err = flash_write(flash_dev, addr, msg, sizeof(struct sensor_message));
    
    if (err == 0) {
        ctx.write_offset += ENTRY_SIZE;
        ctx.total_count++;
        save_context();
    } else {
        LOG_ERR("Write failed: %d", err);
    }
}

int flash_storage_read(struct sensor_message *msgs, int count)
{
    /** 
     * Simple Read: Reads 'count' messages from the CURRENT active slot (newest data).
     * Does not iterate backwards through previous slots yet.
     */
    int read = 0;
    uint32_t off = 0;
    uint32_t base_addr = STORAGE_START_OFFSET + (ctx.current_slot * SECTOR_SIZE);

    while (read < count && off < ctx.write_offset) {
        flash_read(flash_dev, base_addr + off, &msgs[read], sizeof(struct sensor_message));
        read++;
        off += ENTRY_SIZE;
    }
    return read;
}

uint32_t flash_storage_get_count(void)
{
    uint32_t cnt = 0;
    for (int i = 0; i < USED_SLOTS; i++) {
        if (ctx.slot_valid[i]) {
            if (i == ctx.current_slot) {
                cnt += (ctx.write_offset / ENTRY_SIZE);
            } else {
                cnt += ENTRIES_PER_SECTOR;
            }
        }
    }
    return cnt;
}

int flash_storage_clear(void)
{
    LOG_INF("Clearing flash");
    int err = flash_erase(flash_dev, STORAGE_START_OFFSET, (USED_SLOTS + 1) * SECTOR_SIZE);
    if (err == 0) {
        ctx.current_slot = 0;
        ctx.write_offset = 0;
        ctx.total_count = 0;
        memset(ctx.slot_valid, 0, sizeof(ctx.slot_valid));
        meta_write_offset = 0;
        save_context();
        LOG_INF("Cleared.");
    }
    return err;
}
```

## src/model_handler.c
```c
#include <zephyr/bluetooth/bluetooth.h>
#include <zephyr/bluetooth/mesh.h>
#include <zephyr/logging/log.h>
#include <zephyr/sys/byteorder.h>
#include "model_handler.h"

LOG_MODULE_REGISTER(model_handler, LOG_LEVEL_INF);

// Publish config constants
#define GROUP_ADDR 0xC000
#define DEFAULT_TTL 3
#define DEFAULT_APP_IDX 0

// Define the Health Pub model and Attention callbacks 
static struct k_work_delayable attention_blink_work;
static bool attention;
static uint16_t central_addr = 0x0;

static struct model_cbs mdl_cbs = {
    .gw_cb = NULL,
    .led_cb = NULL,
};

static void attention_blink(struct k_work *work) {
	static int idx;
	const uint8_t pattern[] = {
		BIT(0) | BIT(1),
		BIT(1) | BIT(2),
		BIT(2) | BIT(3),
		BIT(3) | BIT(0),
	};

	if (attention) {
        // Make sure cb isn't NULL first
        if (mdl_cbs.led_cb)
            mdl_cbs.led_cb(pattern[idx++ % ARRAY_SIZE(pattern)]);
		k_work_reschedule(&attention_blink_work, K_MSEC(30));
	} else {
        if (mdl_cbs.led_cb)
            mdl_cbs.led_cb(0);
	}
}

static void attention_on(const struct bt_mesh_model *mod) {
	attention = true;
	k_work_reschedule(&attention_blink_work, K_NO_WAIT);
}

static void attention_off(const struct bt_mesh_model *mod) {
	attention = false;
}

static const struct bt_mesh_health_srv_cb health_srv_cb = {
	.attn_on = attention_on,
	.attn_off = attention_off,
};

static struct bt_mesh_health_srv health_srv = {
	.cb = &health_srv_cb,
};

BT_MESH_HEALTH_PUB_DEFINE(health_pub, 0);

/** 
 * Publication context - required for the model to send messages
 * Buffer can hold a payload of 2 bytes for sync and control messages.
 * Sensor readings are published using a different buffer.
 */
BT_MESH_MODEL_PUB_DEFINE(vnd_pub, NULL, BT_MESH_MODEL_BUF_LEN(BT_MESH_MODEL_OP_EST_CENTRAL, 2));

// Message handlers
/**
 * @brief Handler for receiving the OP_MESSAGE
 */
static int handle_message(const struct bt_mesh_model *model,
                          struct bt_mesh_msg_ctx *ctx,
                          struct net_buf_simple *buf)
{
    uint8_t gw_buf[MAX_SNS_MSG_LEN];

    // Copy received data to a local buffer
    memcpy(gw_buf, buf->data, buf->len);

    // Ignore messages from current node
    // First byte of the message is always the count (number of readings received)
    if (bt_mesh_model_elem(model)->rt->addr == ctx->addr) {
        LOG_INF("Received own message (count: %d)", gw_buf[0]);
    } else {
        LOG_INF("RX Batch from 0x%04x (count: %d)", ctx->addr, gw_buf[0]);
    }

    // Send data to be processed if the node acts as gateway
    if (mdl_cbs.gw_cb)
        mdl_cbs.gw_cb(gw_buf, buf->len, ctx->addr);

    return 0;
}

static int handle_est_central(const struct bt_mesh_model *model,
                          struct bt_mesh_msg_ctx *ctx,
                          struct net_buf_simple *buf) {
    central_addr = ctx->addr;
    LOG_INF("Central has been established as 0x%04x", central_addr);
    return 0;
}

static int handle_cancel_central(const struct bt_mesh_model *model,
                            struct bt_mesh_msg_ctx *ctx,
                            struct net_buf_simple *buf) {
    if (ctx->addr == central_addr) {
        central_addr = 0x0;
        LOG_INF("Central lost");
    } else {
        if (bt_mesh_model_elem(model)->rt->addr == ctx->addr)
            LOG_INF("This node is no longer central");
        else
            LOG_INF("Node 0x%04x announced it is no longer central, but 0x%04x is already central. Ignoring", ctx->addr, central_addr);
    }

    return 0;
}

/**
 * Mapping of OpCodes to Handler Functions
 * 
 * Ops:
 * - Message: An array of sensor readings (serialized sensor_message structs). One extra byte on the min length since
 * the first byte of the payload represents the number of readings transmitted. 10 readings max limit. 
 * - Establish central: Sent by a node that is connected via USB to a host and is selected as Central by the app, unless
 * a node has already declared itself central
 * - Cancel central: Sent by the central node if it's disconnected from the host to let the other nodes know they should
 * stop sending data to it
 * */ 
static const struct bt_mesh_model_op vnd_ops[] = {
    { BT_MESH_MODEL_OP_MESSAGE, BT_MESH_LEN_MIN(MIN_SNS_MSG_LEN), handle_message },
    { BT_MESH_MODEL_OP_EST_CENTRAL, BT_MESH_LEN_EXACT(2), handle_est_central },
    { BT_MESH_MODEL_OP_CANCEL_CENTRAL, BT_MESH_LEN_EXACT(2), handle_cancel_central },
    BT_MESH_MODEL_OP_END,
};

// Model Definition

// Declare the standard SIG models needed for every mesh node
static struct bt_mesh_model sig_models[] = {
	BT_MESH_MODEL_CFG_SRV,
	BT_MESH_MODEL_HEALTH_SRV(&health_srv, &health_pub),
};

// Define a Vendor Model using the BT_MESH_MODEL_VND macro
// Args: Company ID, Model ID, Opcode List, Publication Data, User Data (NULL) 
static struct bt_mesh_model vnd_models[] = {
    BT_MESH_MODEL_VND(TEST_VND_COMPANY_ID, TEST_VND_MODEL_ID, vnd_ops, &vnd_pub, NULL),
};

// Element configuration (the node's capabilities)
static const struct bt_mesh_elem elements[] = {
	BT_MESH_ELEM(0, sig_models, vnd_models),
};

// Node composition
const struct bt_mesh_comp comp = {
    .cid = TEST_VND_COMPANY_ID,
    .elem = elements,
    .elem_count = ARRAY_SIZE(elements),
};

// Public Functions
void configure_model(void) {
    struct bt_mesh_model *mod = &vnd_models[0];
    bool bound = false;
    // Bind default app key to model
    // Check if already bound
    for (int i = 0; i < CONFIG_BT_MESH_MODEL_KEY_COUNT; i++) {
        if (mod->keys[i] == DEFAULT_APP_IDX) {
            bound = true;
            break;
        }
    }

    // Bind if not found
    if (!bound) {
        for (int i = 0; i < CONFIG_BT_MESH_MODEL_KEY_COUNT; i++) {
            if (mod->keys[i] == BT_MESH_KEY_UNUSED) {
                mod->keys[i] = DEFAULT_APP_IDX;
                LOG_INF("Auto-bound AppKey to Vendor Model");
                break;
            }
        }
    }

    // Set publication parameters
    // Publication address, ttl and retransmit policy are identical for every node and
    // know at boot
    vnd_pub.addr = GROUP_ADDR;
    vnd_pub.ttl  = DEFAULT_TTL;
    vnd_pub.key  = DEFAULT_APP_IDX;
    vnd_pub.retransmit = 0;

    LOG_INF("Auto-configured publication params");

    // Set subscription parameters
    bool subbed = false;

    // Search through the vendor model's list of subscribed groups for the default group address
    for (int i = 0; i < CONFIG_BT_MESH_MODEL_GROUP_COUNT; i++) {
        if (mod->groups[i] == GROUP_ADDR) {
            LOG_INF("Already subbed to default group address");
            subbed = true;
            break;
        }
    }

    // Add group address to sub list if not found already
    if (!subbed) {
        for (int i = 0; i < CONFIG_BT_MESH_MODEL_GROUP_COUNT; i++) {
            if (mod->groups[i] == BT_MESH_ADDR_UNASSIGNED) {
                mod->groups[i] = GROUP_ADDR;
                LOG_INF("Auto-subbed to default group address");
                break;
            }
        }
    }
}

int model_handler_init(const struct model_cbs _mdl_cbs) {
	// Init the work queue object for the attention blink
	k_work_init_delayable(&attention_blink_work, attention_blink);

    // Store callbacks
    mdl_cbs.gw_cb = _mdl_cbs.gw_cb;
    mdl_cbs.led_cb = _mdl_cbs.led_cb;

    // Apply default config
    // configure_model();

	return 0;
}

int model_handler_send(struct sensor_message *msgs, uint8_t count) {
    if (vnd_pub.addr == BT_MESH_ADDR_UNASSIGNED) {
        LOG_WRN("Publication address not set! Provision and configure the node first.");
        return -EADDRNOTAVAIL;
    }

    if (count == 0) {
        LOG_WRN("Attempt to publish empty message.");
        return -EINVAL;
    }

    if (count > MAX_BATCH_SIZE) {
        LOG_ERR("Batch size %d exceeds limit %d", count, MAX_BATCH_SIZE);
        return -EOVERFLOW;
    }

    // Buffer payload len includes 1 byte for the message count
    BT_MESH_MODEL_BUF_DEFINE(msg, BT_MESH_MODEL_OP_MESSAGE, MAX_SNS_MSG_LEN);
    // Init message with op code
    bt_mesh_model_msg_init(&msg, BT_MESH_MODEL_OP_MESSAGE);

    net_buf_simple_add_u8(&msg, count);

    for (uint8_t i = 0; i < count; i++) {
        net_buf_simple_add_u8(&msg, msgs[i].type);
        net_buf_simple_add_le32(&msg, msgs[i].timestamp);
        net_buf_simple_add_le32(&msg, (uint32_t)msgs[i].value);
    }

    struct bt_mesh_msg_ctx ctx = {
        .addr = vnd_pub.addr,
        .app_idx = vnd_pub.key,
        .send_ttl = vnd_pub.ttl,
        .send_rel = false,
    };

    return bt_mesh_model_send(vnd_models, &ctx, &msg, NULL, NULL);
}

int model_handler_est_central(void) {
    if (vnd_pub.addr == BT_MESH_ADDR_UNASSIGNED) {
        LOG_WRN("Publication address not set! Provision and configure the node first.");
        return -EADDRNOTAVAIL;
    }

    // No data to transmit, but message buffer must be initialized with op code
    bt_mesh_model_msg_init(vnd_pub.msg, BT_MESH_MODEL_OP_EST_CENTRAL);
    net_buf_simple_add_le16(vnd_pub.msg, 0);
    int err = bt_mesh_model_publish(vnd_models);
    if (err) {
        LOG_ERR("Failed to publish (err %d)", err);
    }

    return err;
}

int model_handler_cancel_central(void) {
    int err = 0;

    // If this node was disconnected from the USB while acting as central,
    // it should announce to the other nodes that it can no longer be central

    central_addr = 0x0;
    // No data to transmit, but message buffer must be initialized with op code
    bt_mesh_model_msg_init(vnd_pub.msg, BT_MESH_MODEL_OP_CANCEL_CENTRAL);
    net_buf_simple_add_le16(vnd_pub.msg, 0);
    err = bt_mesh_model_publish(vnd_models);
    if (err) {
        LOG_ERR("Failed to publish (err %d)", err);
    }

    return err;
}

uint16_t get_central_address() {
    return central_addr;
}

bool central_exists() {
    return (central_addr != 0x0);
}
```
